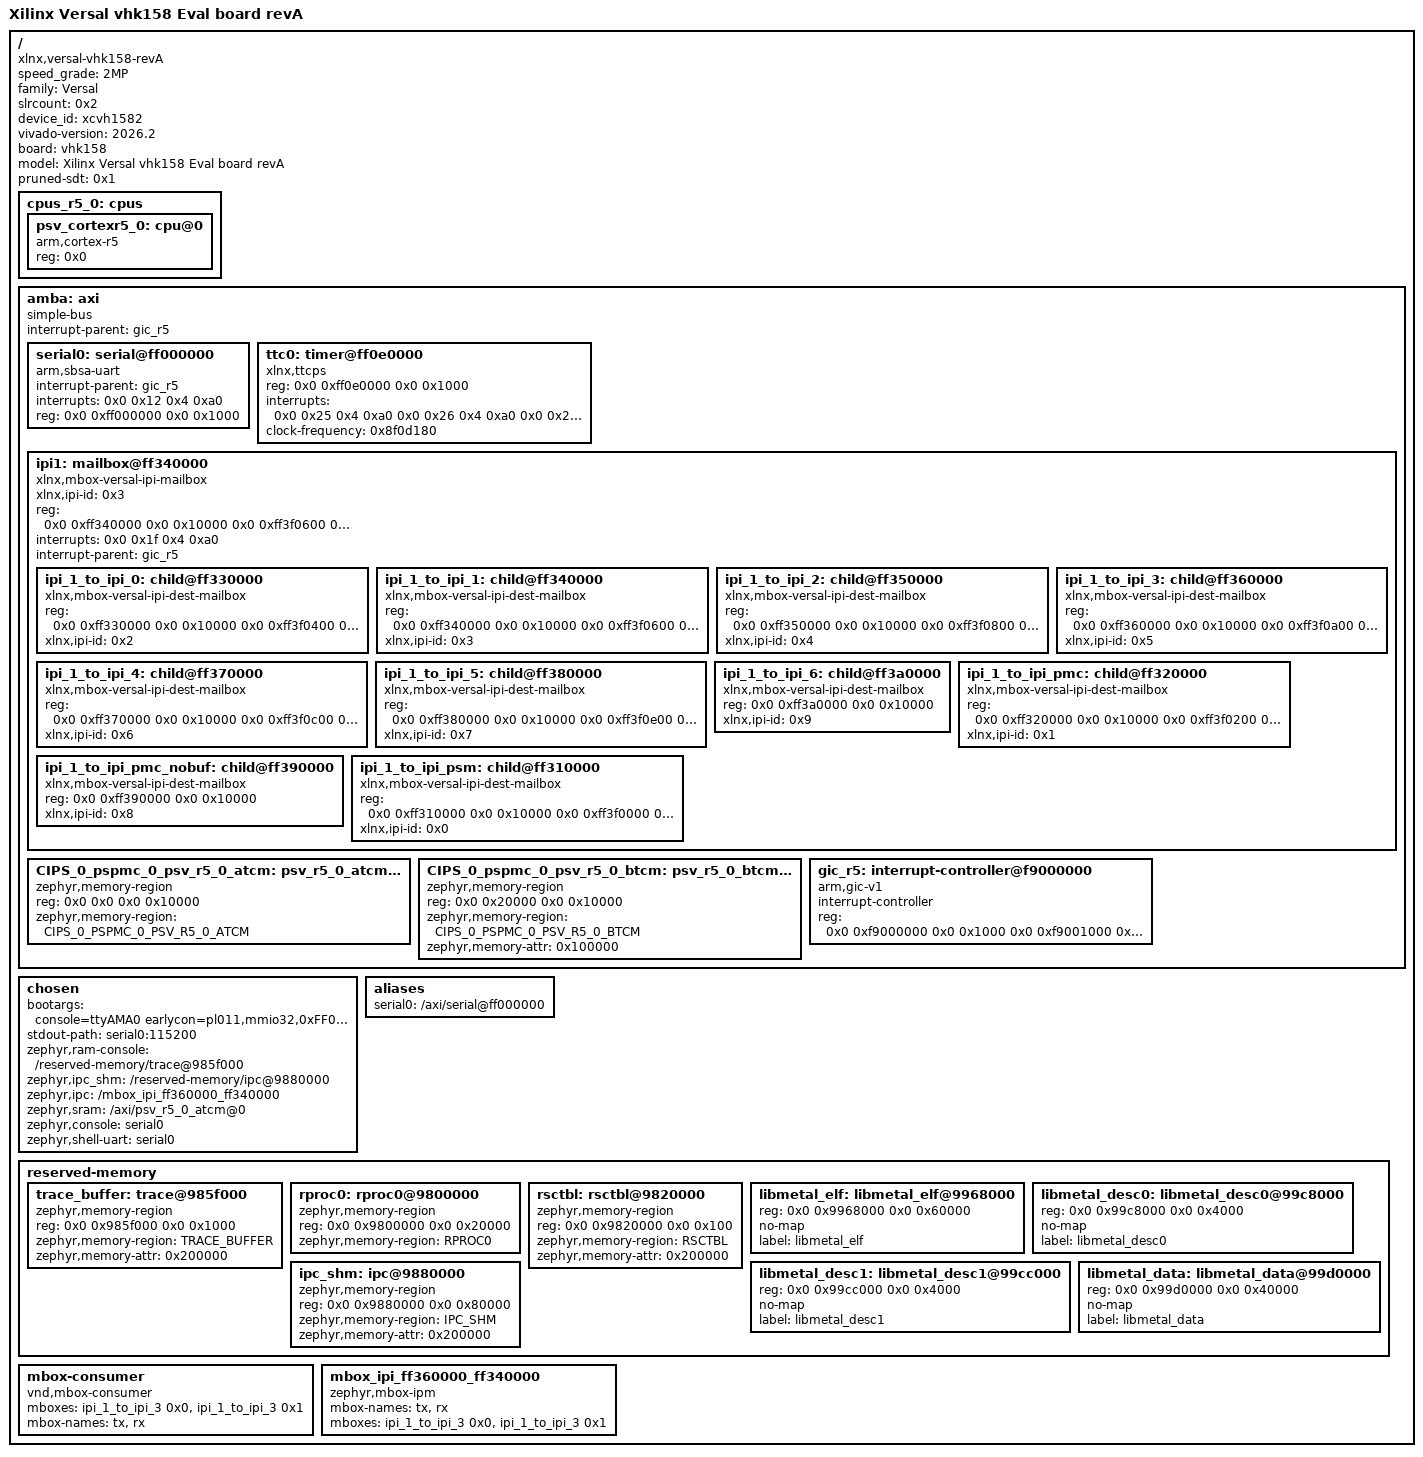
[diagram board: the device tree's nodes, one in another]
/dts-v1/;
/ {
        speed_grade = "2MP";
        family = "Versal";
        slrcount = <0x2>;
        device_id = "xcvh1582";
        vivado-version = "2026.2";
        board = "vhk158";
        model = "Xilinx Versal vhk158 Eval board revA";
        #size-cells = <0x2>;
        #address-cells = <0x2>;
        compatible = "xlnx,versal-vhk158-revA", "xlnx,versal-vhk158", "xlnx,versal";
        pruned-sdt = <0x1>;

        cpus_r5_0: cpus {
                phandle = <0xcb>;
                #size-cells = <0x0>;
                #address-cells = <0x1>;

                psv_cortexr5_0: cpu@0 {
                        phandle = <0xcc>;
                        reg = <0x0>;
                        device_type = "cpu";
                        compatible = "arm,cortex-r5";
                };
        };

        amba: axi {
                phandle = <0x1>;
                bootph-all;
                interrupt-parent = <&gic_r5>;
                ranges;
                #size-cells = <0x2>;
                #address-cells = <0x2>;
                compatible = "simple-bus";

                serial0: serial@ff000000 {
                        phandle = <0x6d>;
                        interrupt-parent = <&gic_r5>;
                        interrupts = <0x0 0x12 0x4 0xa0>;
                        reg = <0x0 0xff000000 0x0 0x1000>;
                        status = "okay";
                        compatible = "arm,sbsa-uart";
                        interrupt-names = "serial0";
                };

                ttc0: timer@ff0e0000 {
                        phandle = <0x73>;
                        reg = <0x0 0xff0e0000 0x0 0x1000>;
                        interrupts = <0x0 0x25 0x4 0xa0 0x0 0x26 0x4 0xa0 0x0 0x27 0x4 0xa0>;
                        status = "okay";
                        compatible = "xlnx,ttcps";
                        interrupt-names = "irq_0", "irq_1", "irq_2";
                        clock-frequency = <0x8f0d180>;
                };

                ipi1: mailbox@ff340000 {
                        phandle = <0x9d>;
                        reg-names = "ctrl", "msg";
                        #size-cells = <0x2>;
                        #address-cells = <0x2>;
                        xlnx,ipi-id = <0x3>;
                        reg = <0x0 0xff340000 0x0 0x10000 0x0 0xff3f0600 0x0 0x200>;
                        interrupts = <0x0 0x1f 0x4 0xa0>;
                        interrupt-parent = <&gic_r5>;
                        compatible = "xlnx,mbox-versal-ipi-mailbox";

                        ipi_1_to_ipi_0: child@ff330000 {
                                phandle = <0x11b>;
                                reg-names = "ctrl", "msg";
                                reg = <0x0 0xff330000 0x0 0x10000 0x0 0xff3f0400 0x0 0x200>;
                                xlnx,ipi-id = <0x2>;
                                #mbox-cells = <0x1>;
                                compatible = "xlnx,mbox-versal-ipi-dest-mailbox";
                        };

                        ipi_1_to_ipi_1: child@ff340000 {
                                phandle = <0x11c>;
                                reg-names = "ctrl", "msg";
                                reg = <0x0 0xff340000 0x0 0x10000 0x0 0xff3f0600 0x0 0x200>;
                                xlnx,ipi-id = <0x3>;
                                #mbox-cells = <0x1>;
                                compatible = "xlnx,mbox-versal-ipi-dest-mailbox";
                        };

                        ipi_1_to_ipi_2: child@ff350000 {
                                phandle = <0x11d>;
                                reg-names = "ctrl", "msg";
                                reg = <0x0 0xff350000 0x0 0x10000 0x0 0xff3f0800 0x0 0x200>;
                                xlnx,ipi-id = <0x4>;
                                #mbox-cells = <0x1>;
                                compatible = "xlnx,mbox-versal-ipi-dest-mailbox";
                        };

                        ipi_1_to_ipi_3: child@ff360000 {
                                phandle = <0x11e>;
                                reg-names = "ctrl", "msg";
                                reg = <0x0 0xff360000 0x0 0x10000 0x0 0xff3f0a00 0x0 0x200>;
                                xlnx,ipi-id = <0x5>;
                                #mbox-cells = <0x1>;
                                compatible = "xlnx,mbox-versal-ipi-dest-mailbox";
                        };

                        ipi_1_to_ipi_4: child@ff370000 {
                                phandle = <0x11f>;
                                reg-names = "ctrl", "msg";
                                reg = <0x0 0xff370000 0x0 0x10000 0x0 0xff3f0c00 0x0 0x200>;
                                xlnx,ipi-id = <0x6>;
                                #mbox-cells = <0x1>;
                                compatible = "xlnx,mbox-versal-ipi-dest-mailbox";
                        };

                        ipi_1_to_ipi_5: child@ff380000 {
                                phandle = <0x120>;
                                reg-names = "ctrl", "msg";
                                reg = <0x0 0xff380000 0x0 0x10000 0x0 0xff3f0e00 0x0 0x200>;
                                xlnx,ipi-id = <0x7>;
                                #mbox-cells = <0x1>;
                                compatible = "xlnx,mbox-versal-ipi-dest-mailbox";
                        };

                        ipi_1_to_ipi_6: child@ff3a0000 {
                                phandle = <0x121>;
                                reg-names = "ctrl";
                                reg = <0x0 0xff3a0000 0x0 0x10000>;
                                xlnx,ipi-id = <0x9>;
                                #mbox-cells = <0x1>;
                                compatible = "xlnx,mbox-versal-ipi-dest-mailbox";
                        };

                        ipi_1_to_ipi_pmc: child@ff320000 {
                                phandle = <0x122>;
                                reg-names = "ctrl", "msg";
                                reg = <0x0 0xff320000 0x0 0x10000 0x0 0xff3f0200 0x0 0x200>;
                                xlnx,ipi-id = <0x1>;
                                #mbox-cells = <0x1>;
                                compatible = "xlnx,mbox-versal-ipi-dest-mailbox";
                        };

                        ipi_1_to_ipi_pmc_nobuf: child@ff390000 {
                                phandle = <0x123>;
                                reg-names = "ctrl";
                                reg = <0x0 0xff390000 0x0 0x10000>;
                                xlnx,ipi-id = <0x8>;
                                #mbox-cells = <0x1>;
                                compatible = "xlnx,mbox-versal-ipi-dest-mailbox";
                        };

                        ipi_1_to_ipi_psm: child@ff310000 {
                                phandle = <0x124>;
                                reg-names = "ctrl", "msg";
                                reg = <0x0 0xff310000 0x0 0x10000 0x0 0xff3f0000 0x0 0x200>;
                                xlnx,ipi-id = <0x0>;
                                #mbox-cells = <0x1>;
                                compatible = "xlnx,mbox-versal-ipi-dest-mailbox";
                        };
                };

                CIPS_0_pspmc_0_psv_r5_0_atcm: psv_r5_0_atcm@0 {
                        phandle = <0x9e>;
                        reg = <0x0 0x0 0x0 0x10000>;
                        status = "okay";
                        compatible = "zephyr,memory-region", "xlnx,psv-r5-tcm-1.0";
                        zephyr,memory-region = "CIPS_0_PSPMC_0_PSV_R5_0_ATCM";
                };

                CIPS_0_pspmc_0_psv_r5_0_btcm: psv_r5_0_btcm@20000 {
                        phandle = <0xa0>;
                        reg = <0x0 0x20000 0x0 0x10000>;
                        status = "okay";
                        compatible = "zephyr,memory-region", "xlnx,psv-r5-tcm-1.0";
                        zephyr,memory-region = "CIPS_0_PSPMC_0_PSV_R5_0_BTCM";
                        zephyr,memory-attr = <0x100000>;
                };

                gic_r5: interrupt-controller@f9000000 {
                        phandle = <0xa1>;
                        compatible = "arm,gic-v1", "arm,gic";
                        #interrupt-cells = <0x4>;
                        interrupt-controller;
                        status = "okay";
                        reg = <0x0 0xf9000000 0x0 0x1000 0x0 0xf9001000 0x0 0x1000>;
                };
        };

        chosen {
                bootargs = "console=ttyAMA0 earlycon=pl011,mmio32,0xFF000000,115200n8 clk_ignore_unused";
                stdout-path = "serial0:115200";
                zephyr,ram-console = "/reserved-memory/trace@985f000";
                zephyr,ipc_shm = "/reserved-memory/ipc@9880000";
                zephyr,ipc = "/mbox_ipi_ff360000_ff340000";
                zephyr,sram = "/axi/psv_r5_0_atcm@0";
                zephyr,console = "serial0";
                zephyr,shell-uart = "serial0";
        };

        aliases {
                serial0 = "/axi/serial@ff000000";
        };

        reserved-memory {
                #address-cells = <0x2>;
                #size-cells = <0x2>;
                ranges;

                trace_buffer: trace@985f000 {
                        phandle = <0x18c>;
                        reg = <0x0 0x985f000 0x0 0x1000>;
                        compatible = "zephyr,memory-region";
                        zephyr,memory-region = "TRACE_BUFFER";
                        zephyr,memory-attr = <0x200000>;
                };

                rproc0: rproc0@9800000 {
                        phandle = <0x18b>;
                        reg = <0x0 0x9800000 0x0 0x20000>;
                        compatible = "zephyr,memory-region";
                        zephyr,memory-region = "RPROC0";
                };

                rsctbl: rsctbl@9820000 {
                        phandle = <0x18d>;
                        reg = <0x0 0x9820000 0x0 0x100>;
                        compatible = "zephyr,memory-region";
                        zephyr,memory-region = "RSCTBL";
                        zephyr,memory-attr = <0x200000>;
                };

                libmetal_elf: libmetal_elf@9968000 {
                        phandle = <0x194>;
                        reg = <0x0 0x9968000 0x0 0x60000>;
                        no-map;
                        label = "libmetal_elf";
                };

                libmetal_desc0: libmetal_desc0@99c8000 {
                        phandle = <0x191>;
                        reg = <0x0 0x99c8000 0x0 0x4000>;
                        no-map;
                        label = "libmetal_desc0";
                };

                libmetal_desc1: libmetal_desc1@99cc000 {
                        phandle = <0x192>;
                        reg = <0x0 0x99cc000 0x0 0x4000>;
                        no-map;
                        label = "libmetal_desc1";
                };

                libmetal_data: libmetal_data@99d0000 {
                        phandle = <0x193>;
                        reg = <0x0 0x99d0000 0x0 0x40000>;
                        no-map;
                        label = "libmetal_data";
                };

                ipc_shm: ipc@9880000 {
                        phandle = <0x195>;
                        reg = <0x0 0x9880000 0x0 0x80000>;
                        compatible = "zephyr,memory-region", "mmio-sram";
                        status = "okay";
                        zephyr,memory-region = "IPC_SHM";
                        zephyr,memory-attr = <0x200000>;
                };
        };

        mbox-consumer {
                compatible = "vnd,mbox-consumer";
                mboxes = <&ipi_1_to_ipi_3 0x0>,
                 <&ipi_1_to_ipi_3 0x1>;
                mbox-names = "tx", "rx";
        };

        mbox_ipi_ff360000_ff340000 {
                compatible = "zephyr,mbox-ipm";
                mbox-names = "tx", "rx";
                status = "okay";
                mboxes = <&ipi_1_to_ipi_3 0x0>,
                 <&ipi_1_to_ipi_3 0x1>;
        };

        __symbols__ {
                cpus_r5_0 = "/cpus";
                psv_cortexr5_0 = "/cpus/cpu@0";
                amba = "/axi";
                serial0 = "/axi/serial@ff000000";
                ttc0 = "/axi/timer@ff0e0000";
                ipi1 = "/axi/mailbox@ff340000";
                ipi_1_to_ipi_0 = "/axi/mailbox@ff340000/child@ff330000";
                ipi_1_to_ipi_1 = "/axi/mailbox@ff340000/child@ff340000";
                ipi_1_to_ipi_2 = "/axi/mailbox@ff340000/child@ff350000";
                ipi_1_to_ipi_3 = "/axi/mailbox@ff340000/child@ff360000";
                ipi_1_to_ipi_4 = "/axi/mailbox@ff340000/child@ff370000";
                ipi_1_to_ipi_5 = "/axi/mailbox@ff340000/child@ff380000";
                ipi_1_to_ipi_6 = "/axi/mailbox@ff340000/child@ff3a0000";
                ipi_1_to_ipi_pmc = "/axi/mailbox@ff340000/child@ff320000";
                ipi_1_to_ipi_pmc_nobuf = "/axi/mailbox@ff340000/child@ff390000";
                ipi_1_to_ipi_psm = "/axi/mailbox@ff340000/child@ff310000";
                CIPS_0_pspmc_0_psv_r5_0_atcm = "/axi/psv_r5_0_atcm@0";
                CIPS_0_pspmc_0_psv_r5_0_btcm = "/axi/psv_r5_0_btcm@20000";
                gic_r5 = "/axi/interrupt-controller@f9000000";
                trace_buffer = "/reserved-memory/trace@985f000";
                rproc0 = "/reserved-memory/rproc0@9800000";
                rsctbl = "/reserved-memory/rsctbl@9820000";
                libmetal_elf = "/reserved-memory/libmetal_elf@9968000";
                libmetal_desc0 = "/reserved-memory/libmetal_desc0@99c8000";
                libmetal_desc1 = "/reserved-memory/libmetal_desc1@99cc000";
                libmetal_data = "/reserved-memory/libmetal_data@99d0000";
                ipc_shm = "/reserved-memory/ipc@9880000";
        };
};
